AUTOSAR XML (schema 314)
package /ComponentType
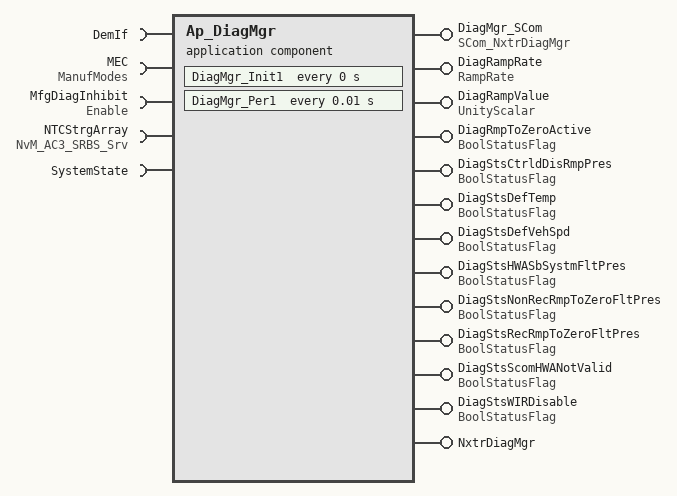
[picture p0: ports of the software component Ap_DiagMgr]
  application software component type Ap_DiagMgr
    13 x provide port:
      DiagMgr_SCom: provided-interface=SCom_NxtrDiagMgr
        provided-com-specs:
          operation=ClearBlackBox, queue-length=1
          operation=GetNTCInfo, queue-length=1
          operation=ReadStrgArray, queue-length=1
          operation=ResetNTCStatus, queue-length=1
      DiagRampRate: unqueued-sender-com-spec{data-element=XpmS_f32, can-invalidate=false, init-value=D_ZERO_ULS_F32}, provided-interface=RampRate
      DiagRampValue: unqueued-sender-com-spec{data-element=Uls_f32, can-invalidate=false, init-value=D_ZERO_ULS_F32}, provided-interface=UnityScalar
      DiagRmpToZeroActive: unqueued-sender-com-spec{data-element=Cnt_lgc, can-invalidate=false, init-value=D_FALSE_CNT_LGC}, provided-interface=BoolStatusFlag
      DiagStsCtrldDisRmpPres: unqueued-sender-com-spec{data-element=Cnt_lgc, can-invalidate=false, init-value=D_FALSE_CNT_LGC}, provided-interface=BoolStatusFlag
      DiagStsDefTemp: unqueued-sender-com-spec{data-element=Cnt_lgc, can-invalidate=false, init-value=D_FALSE_CNT_LGC}, provided-interface=BoolStatusFlag
      DiagStsDefVehSpd: unqueued-sender-com-spec{data-element=Cnt_lgc, can-invalidate=false, init-value=D_FALSE_CNT_LGC}, provided-interface=BoolStatusFlag
      DiagStsHWASbSystmFltPres: unqueued-sender-com-spec{data-element=Cnt_lgc, can-invalidate=false, init-value=D_FALSE_CNT_LGC}, provided-interface=BoolStatusFlag
      DiagStsNonRecRmpToZeroFltPres: unqueued-sender-com-spec{data-element=Cnt_lgc, can-invalidate=false, init-value=D_FALSE_CNT_LGC}, provided-interface=BoolStatusFlag
      DiagStsRecRmpToZeroFltPres: unqueued-sender-com-spec{data-element=Cnt_lgc, can-invalidate=false, init-value=D_FALSE_CNT_LGC}, provided-interface=BoolStatusFlag
      DiagStsScomHWANotValid: unqueued-sender-com-spec{data-element=Cnt_lgc, can-invalidate=false, init-value=D_FALSE_CNT_LGC}, provided-interface=BoolStatusFlag
      DiagStsWIRDisable: unqueued-sender-com-spec{data-element=Cnt_lgc, can-invalidate=false, init-value=D_FALSE_CNT_LGC}, provided-interface=BoolStatusFlag
      NxtrDiagMgr: provided-interface=NxtrDiagMgr
        provided-com-specs:
          operation=GetNTCActive, queue-length=1
          operation=GetNTCFailed, queue-length=1
          operation=GetNTCStatus, queue-length=1
          operation=SetNTCStatus, queue-length=1
    5 x require port:
      DemIf: required-com-specs=[DemShutdown, RestartDem, SetEventStatus, SetOperationCycleState], required-interface=DemIf
      MEC: unqueued-receiver-com-spec{data-element=Cnt_enum, init-value=D_MANUFMODEINIT_CNT_ENUM}, required-interface=ManufModes
      MfgDiagInhibit: unqueued-receiver-com-spec{data-element=Cnt_lgc, init-value=D_FALSE_CNT_LGC}, required-interface=Enable
      NTCStrgArray: required-com-specs=[EraseBlock, GetErrorStatus, InvalidateNvBlock, ReadBlock, SetRamBlockStatus, WriteBlock], required-interface=NvM_AC3_SRBS_Srv
      SystemState: required-interface=SystemState
  internal behavior Ap_DiagMgr_InternalBehavior: component=Ap_DiagMgr
    timing event DiagMgr_Init1_InitEvent: start-on-event=DiagMgr_Init1, period=0
    timing event TMT_DiagMgr_Per1: mode-dependency=dependent-on-mode=SystemState.Mode.OFF, start-on-event=DiagMgr_Per1, period=0.01
    operation invoked event OIT_DiagMgr_SCom_ReadStrgArray_DiagMgr_SCom_ReadStrgArray: start-on-event=DiagMgr_SCom_ReadStrgArray, operation=DiagMgr_SCom.ReadStrgArray
    mode switch event MST_DiagMgr_Trns1_0: start-on-event=DiagMgr_Trns1, activation=ENTRY, mode=SystemState.Mode.OFF
    mode switch event MST_DiagMgr_Trns2_0: start-on-event=DiagMgr_Trns2, activation=EXIT, mode=SystemState.Mode.OFF
    4 x operation invoked event:
      OIT_NxtrDiagMgr_GetNTCActive_NxtrDiagMgr_GetNTCActive: start-on-event=NxtrDiagMgr_GetNTCActive, operation=NxtrDiagMgr.GetNTCActive
      OIT_NxtrDiagMgr_GetNTCFailed_NxtrDiagMgr_GetNTCFailed: start-on-event=NxtrDiagMgr_GetNTCFailed, operation=NxtrDiagMgr.GetNTCFailed
      OIT_NxtrDiagMgr_GetNTCStatus_NxtrDiagMgr_GetNTCStatus: start-on-event=NxtrDiagMgr_GetNTCStatus, operation=NxtrDiagMgr.GetNTCStatus
      OIT_NxtrDiagMgr_SetNTCStatus_NxtrDiagMgr_SetNTCStatus: start-on-event=NxtrDiagMgr_SetNTCStatus, operation=NxtrDiagMgr.SetNTCStatus
    per instance memory NTCStrgArray: type=NTCStrgArray, type-definition=/DataType/NTCStrgArray
    port-api-options:
      enable-take-address=false, indirect-api=false, port=DemIf
      enable-take-address=false, indirect-api=false, port=DiagMgr_SCom
      enable-take-address=false, indirect-api=false, port=DiagRampRate
      enable-take-address=false, indirect-api=false, port=DiagRampValue
      enable-take-address=false, indirect-api=false, port=DiagRmpToZeroActive
      enable-take-address=false, indirect-api=false, port=DiagStsCtrldDisRmpPres
      enable-take-address=false, indirect-api=false, port=DiagStsDefTemp
      enable-take-address=false, indirect-api=false, port=DiagStsDefVehSpd
      enable-take-address=false, indirect-api=false, port=DiagStsHWASbSystmFltPres
      enable-take-address=false, indirect-api=false, port=DiagStsNonRecRmpToZeroFltPres
      enable-take-address=false, indirect-api=false, port=DiagStsRecRmpToZeroFltPres
      enable-take-address=false, indirect-api=false, port=DiagStsScomHWANotValid
      enable-take-address=false, indirect-api=false, port=DiagStsWIRDisable
      enable-take-address=false, indirect-api=false, port=MEC
      enable-take-address=false, indirect-api=false, port=MfgDiagInhibit
      enable-take-address=false, indirect-api=false, port=NTCStrgArray
      enable-take-address=false, indirect-api=false, port=NxtrDiagMgr
      enable-take-address=false, indirect-api=false, port=SystemState
    12 x runnable:
      DiagMgr_Init1
      DiagMgr_Per1
        11 x data send point:
          SEND_DiagRampRate_XpmS_f32: data-element=DiagRampRate.XpmS_f32
          SEND_DiagRampValue_Uls_f32: data-element=DiagRampValue.Uls_f32
          SEND_DiagRmpToZeroActive_Cnt_lgc: data-element=DiagRmpToZeroActive.Cnt_lgc
          SEND_DiagStsCtrldDisRmpPres_Cnt_lgc: data-element=DiagStsCtrldDisRmpPres.Cnt_lgc
          SEND_DiagStsDefTemp_Cnt_lgc: data-element=DiagStsDefTemp.Cnt_lgc
          SEND_DiagStsDefVehSpd_Cnt_lgc: data-element=DiagStsDefVehSpd.Cnt_lgc
          SEND_DiagStsHWASbSystmFltPres_Cnt_lgc: data-element=DiagStsHWASbSystmFltPres.Cnt_lgc
          SEND_DiagStsNonRecRmpToZeroFltPres_Cnt_lgc: data-element=DiagStsNonRecRmpToZeroFltPres.Cnt_lgc
          SEND_DiagStsRecRmpToZeroFltPres_Cnt_lgc: data-element=DiagStsRecRmpToZeroFltPres.Cnt_lgc
          SEND_DiagStsScomHWANotValid_Cnt_lgc: data-element=DiagStsScomHWANotValid.Cnt_lgc
          SEND_DiagStsWIRDisable_Cnt_lgc: data-element=DiagStsWIRDisable.Cnt_lgc
        sync call SC_DemIf_SetEventStatus: operation=DemIf.SetEventStatus, timeout=0
      DiagMgr_SCom_GetNTCParamByte
      DiagMgr_SCom_ReadStrgArray
      DiagMgr_Trns1
        sync call SC_NTCStrgArray_SetRamBlockStatus: operation=NTCStrgArray.SetRamBlockStatus, timeout=0
      DiagMgr_Trns2
        sync call SC_DemIf_RestartDem: operation=DemIf.RestartDem, timeout=0
      NxtrDiagMgr_GetNTCActive: can-be-invoked-concurrently=true
      NxtrDiagMgr_GetNTCFailed: can-be-invoked-concurrently=true
      NxtrDiagMgr_GetNTCStatus: can-be-invoked-concurrently=true
      NxtrDiagMgr_ResetEventStatus: can-be-invoked-concurrently=true
      NxtrDiagMgr_SetNTCStatus: can-be-invoked-concurrently=true
        data receive point REC_MEC_Cnt_enum: data-element=MEC.Cnt_enum
        data receive point REC_MfgDiagInhibit_Cnt_lgc: data-element=MfgDiagInhibit.Cnt_lgc
        11 x data send point:
          SEND_DiagRampRate_XpmS_f32: data-element=DiagRampRate.XpmS_f32
          SEND_DiagRampValue_Uls_f32: data-element=DiagRampValue.Uls_f32
          SEND_DiagRmpToZeroActive_Cnt_lgc: data-element=DiagRmpToZeroActive.Cnt_lgc
          SEND_DiagStsCtrldDisRmpPres_Cnt_lgc: data-element=DiagStsCtrldDisRmpPres.Cnt_lgc
          SEND_DiagStsDefTemp_Cnt_lgc: data-element=DiagStsDefTemp.Cnt_lgc
          SEND_DiagStsDefVehSpd_Cnt_lgc: data-element=DiagStsDefVehSpd.Cnt_lgc
          SEND_DiagStsHWASbSystmFltPres_Cnt_lgc: data-element=DiagStsHWASbSystmFltPres.Cnt_lgc
          SEND_DiagStsNonRecRmpToZeroFltPres_Cnt_lgc: data-element=DiagStsNonRecRmpToZeroFltPres.Cnt_lgc
          SEND_DiagStsRecRmpToZeroFltPres_Cnt_lgc: data-element=DiagStsRecRmpToZeroFltPres.Cnt_lgc
          SEND_DiagStsScomHWANotValid_Cnt_lgc: data-element=DiagStsScomHWANotValid.Cnt_lgc
          SEND_DiagStsWIRDisable_Cnt_lgc: data-element=DiagStsWIRDisable.Cnt_lgc
      NxtrDiagMgr_SetOperationCycleState
        sync call SC_DemIf_SetOperationCycleState: operation=DemIf.SetOperationCycleState, timeout=0
    service-needss:
      swc nv block needs NTCStrgBlk: n-data-sets=0, readonly=false, reliability=LOW, resistant-to-changed-sw=false, restore-at-start=false, write-only-once=false, writing-frequency=0, writing-priority=LOW, mirror-block=NTCStrgArray
  swc implementation Ap_DiagMgr_Implementation: behavior=Ap_DiagMgr_InternalBehavior
    code-descriptors:
      code Code: type=SRC
